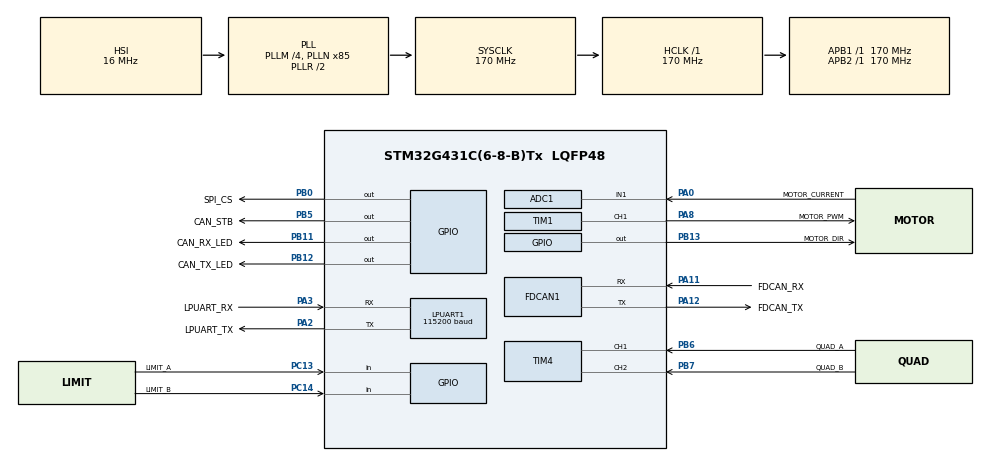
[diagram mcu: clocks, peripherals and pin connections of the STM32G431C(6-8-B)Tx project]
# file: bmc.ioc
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ADC1.Channel-0\#ChannelRegularConversion=ADC_CHANNEL_1
ADC1.NbrOfConversionFlag=1
ADC1.OffsetNumber-0\#ChannelRegularConversion=ADC_OFFSET_NONE
ADC1.Rank-0\#ChannelRegularConversion=1
ADC1.SamplingTime-0\#ChannelRegularConversion=ADC_SAMPLETIME_2CYCLES_5
ADC1.master=1
Dma.LPUART1_TX.0.Direction=DMA_MEMORY_TO_PERIPH
Dma.LPUART1_TX.0.EventEnable=DISABLE
Dma.LPUART1_TX.0.Instance=DMA1_Channel1
Dma.LPUART1_TX.0.MemDataAlignment=DMA_MDATAALIGN_BYTE
Dma.LPUART1_TX.0.MemInc=DMA_MINC_ENABLE
Dma.LPUART1_TX.0.Mode=DMA_NORMAL
Dma.LPUART1_TX.0.PeriphDataAlignment=DMA_PDATAALIGN_BYTE
Dma.LPUART1_TX.0.PeriphInc=DMA_PINC_DISABLE
Dma.LPUART1_TX.0.Polarity=HAL_DMAMUX_REQ_GEN_RISING
Dma.LPUART1_TX.0.Priority=DMA_PRIORITY_LOW
Dma.LPUART1_TX.0.RequestNumber=1
Dma.LPUART1_TX.0.SignalID=NONE
Dma.LPUART1_TX.0.SyncEnable=DISABLE
Dma.LPUART1_TX.0.SyncPolarity=HAL_DMAMUX_SYNC_NO_EVENT
Dma.LPUART1_TX.0.SyncRequestNumber=1
Dma.LPUART1_TX.0.SyncSignalID=NONE
Dma.Request0=LPUART1_TX
FDCAN1.AutoRetransmission=ENABLE
FDCAN1.CalculateBaudRateNominal=999999
FDCAN1.CalculateTimeBitNominal=1000
FDCAN1.CalculateTimeQuantumNominal=11.764705882352942
FDCAN1.ClockDivider=FDCAN_CLOCK_DIV2
FDCAN1.DataSyncJumpWidth=5
FDCAN1.DataTimeSeg1=11
FDCAN1.DataTimeSeg2=5
FDCAN1.ExtFiltersNbr=3
FDCAN1.FrameFormat=FDCAN_FRAME_FD_BRS
FDCAN1.NominalPrescaler=1
FDCAN1.NominalSyncJumpWidth=16
FDCAN1.NominalTimeSeg1=56
FDCAN1.NominalTimeSeg2=28
LPUART1.BaudRate=115200
Mcu.Family=STM32G4
Mcu.Name=STM32G431C(6-8-B)Tx
Mcu.Package=LQFP48
NVIC.DMA1_Channel1_IRQn=true\:7\:0\:true\:false\:true\:false\:true\:true
NVIC.FDCAN1_IT0_IRQn=true\:1\:0\:true\:false\:true\:true\:true\:true
NVIC.FDCAN1_IT1_IRQn=true\:1\:0\:true\:false\:true\:true\:true\:true
NVIC.LPUART1_IRQn=true\:8\:0\:true\:false\:true\:true\:true\:true
NVIC.PriorityGroup=NVIC_PRIORITYGROUP_4
NVIC.TIM1_BRK_TIM15_IRQn=true\:1\:0\:true\:false\:true\:true\:true\:true
NVIC.TIM1_TRG_COM_TIM17_IRQn=true\:1\:0\:true\:false\:true\:true\:true\:true
NVIC.TIM1_UP_TIM16_IRQn=true\:1\:0\:true\:false\:true\:true\:true\:true
NVIC.TIM4_IRQn=true\:1\:0\:true\:false\:true\:true\:true\:true
NVIC.TIM6_DAC_IRQn=true\:0\:0\:false\:false\:true\:true\:true\:true
PA0.GPIO_Label=MOTOR_CURRENT
PA0.Mode=IN1-Single-Ended
PA0.Signal=ADC1_IN1
PA11.GPIO_Label=FDCAN_RX
PA11.GPIO_Speed=GPIO_SPEED_FREQ_VERY_HIGH
PA11.Mode=FDCAN_Activate
PA11.Signal=FDCAN1_RX
PA12.GPIO_Label=FDCAN_TX
PA12.GPIO_Speed=GPIO_SPEED_FREQ_VERY_HIGH
PA12.Mode=FDCAN_Activate
PA12.Signal=FDCAN1_TX
PA13.GPIO_Label=SWDIO
PA13.Mode=Trace_Asynchronous_SW
PA13.Signal=SYS_JTMS-SWDIO
PA14.GPIO_Label=SWCLK
PA14.Mode=Trace_Asynchronous_SW
PA14.Signal=SYS_JTCK-SWCLK
PA2.GPIO_Label=LPUART_TX
PA2.Mode=Asynchronous
PA2.Signal=LPUART1_TX
PA3.GPIO_Label=LPUART_RX
PA3.Mode=Asynchronous
PA3.Signal=LPUART1_RX
PA8.GPIO_Label=MOTOR_PWM
PA8.Signal=S_TIM1_CH1
PB0.GPIO_Label=SPI_CS
PB0.Signal=GPIO_Output
PB11.GPIO_Label=CAN_RX_LED
PB11.Signal=GPIO_Output
PB12.GPIO_Label=CAN_TX_LED
PB12.Signal=GPIO_Output
PB13.GPIO_Label=MOTOR_DIR
PB13.Signal=GPIO_Output
PB3.GPIO_Label=SWO
PB3.Mode=Trace_Asynchronous_SW
PB3.Signal=SYS_JTDO-SWO
PB5.GPIO_Label=CAN_STB
PB5.Signal=GPIO_Output
PB6.GPIO_Label=QUAD_A
PB6.Signal=S_TIM4_CH1
PB7.GPIO_Label=QUAD_B
PB7.Signal=S_TIM4_CH2
PB9.GPIO_FM9=SYSCFG_FASTMODEPLUS_PB9
PB9.GPIO_Label=I2C_SDA
PB9.GPIO_Speed=GPIO_SPEED_FREQ_VERY_HIGH
PB9.Signal=I2C1_SDA
PC13.GPIO_Label=LIMIT_A
PC13.GPIO_PuPd=GPIO_PULLUP
PC13.Signal=GPIO_Input
PC14-OSC32_IN.GPIO_Label=LIMIT_B
PC14-OSC32_IN.GPIO_PuPd=GPIO_PULLUP
PC14-OSC32_IN.Signal=GPIO_Input
ProjectManager.HeapSize=0x200
ProjectManager.StackSize=0x400
ProjectManager.TargetToolchain=CMake
RCC.ADC12Freq_Value=170000000
RCC.AHBFreq_Value=170000000
RCC.APB1Freq_Value=170000000
RCC.APB1TimFreq_Value=170000000
RCC.APB2Freq_Value=170000000
RCC.APB2TimFreq_Value=170000000
RCC.CortexFreq_Value=170000000
RCC.EXTERNAL_CLOCK_VALUE=12288000
RCC.HCLKFreq_Value=170000000
RCC.HSE_VALUE=8000000
RCC.HSI48_VALUE=48000000
RCC.HSI_VALUE=16000000
RCC.LSE_VALUE=32768
RCC.PLLM=RCC_PLLM_DIV4
RCC.PLLN=85
RCC.SYSCLKFreq_VALUE=170000000
RCC.SYSCLKSource=RCC_SYSCLKSOURCE_PLLCLK
RCC.USBFreq_Value=170000000
RCC.VCOOutputFreq_Value=340000000
SH.S_TIM1_CH1.0=TIM1_CH1,PWM Generation1 CH1
SH.S_TIM4_CH1.0=TIM4_CH1,Encoder_Interface
SH.S_TIM4_CH2.0=TIM4_CH2,Encoder_Interface
TIM1.Channel-PWM\ Generation1\ CH1=TIM_CHANNEL_1
TIM1.PeriodNoDither=99
TIM1.Prescaler=63
TIM15.PeriodNoDither=54580
TIM15.Prescaler=511
TIM16.PeriodNoDither=9999
TIM16.Prescaler=1699
TIM17.PeriodNoDither=3999
TIM17.Prescaler=1699
TIM2.Prescaler=169
TIM4.EncoderMode=TIM_ENCODERMODE_TI12
TIM4.IC1Filter=15
TIM4.IC2Filter=15
TIM6.AutoReloadPreload=TIM_AUTORELOAD_PRELOAD_ENABLE
TIM6.PeriodNoDither=9999
TIM6.Prescaler=1699
VP_SYS_VS_DBSignals.Mode=DisableDeadBatterySignals
VP_TIM15_VS_ClockSourceINT.Mode=Internal
VP_TIM16_VS_ClockSourceINT.Mode=Enable_Timer
VP_TIM17_VS_ClockSourceINT.Mode=Enable_Timer
VP_TIM2_VS_ClockSourceINT.Mode=Internal
VP_TIM6_VS_ClockSourceINT.Mode=Enable_Timer
VP_TIM8_VS_ClockSourceINT.Mode=Internal
board=custom

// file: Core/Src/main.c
/* USER CODE BEGIN Header */
/**
  ******************************************************************************
  * @file           : main.c
  * @brief          : Main program body
  ******************************************************************************
  * @attention
  *
  * Copyright (c) 2025 STMicroelectronics.
  * All rights reserved.
  *
  * This software is licensed under terms that can be found in the LICENSE file
  * in the root directory of this software component.
  * If no LICENSE file comes with this software, it is provided AS-IS.
  *
  ******************************************************************************
  */
/* USER CODE END Header */
#include "main.h"

ADC_HandleTypeDef hadc1;

FDCAN_HandleTypeDef hfdcan1;

UART_HandleTypeDef hlpuart1;
DMA_HandleTypeDef hdma_lpuart1_tx;

TIM_HandleTypeDef htim1;
TIM_HandleTypeDef htim2;
TIM_HandleTypeDef htim4;
TIM_HandleTypeDef htim6;
TIM_HandleTypeDef htim8;
TIM_HandleTypeDef htim15;
TIM_HandleTypeDef htim16;
TIM_HandleTypeDef htim17;

void SystemClock_Config(void);
static void MX_GPIO_Init(void);
static void MX_DMA_Init(void);
static void MX_FDCAN1_Init(void);
static void MX_LPUART1_UART_Init(void);
static void MX_TIM1_Init(void);
static void MX_TIM2_Init(void);
static void MX_TIM4_Init(void);
static void MX_TIM6_Init(void);
static void MX_TIM8_Init(void);
static void MX_TIM15_Init(void);
static void MX_TIM16_Init(void);
static void MX_TIM17_Init(void);
static void MX_ADC1_Init(void);

int main(void)
{

  /* MCU Configuration--------------------------------------------------------*/

  /* Reset of all peripherals, Initializes the Flash interface and the Systick. */
  HAL_Init();

  /* Configure the system clock */
  SystemClock_Config();

  /* Initialize all configured peripherals */
  MX_GPIO_Init();
  MX_DMA_Init();
  MX_FDCAN1_Init();
  MX_LPUART1_UART_Init();
  MX_TIM1_Init();
  MX_TIM2_Init();
  MX_TIM4_Init();
  MX_TIM6_Init();
  MX_TIM8_Init();
  MX_TIM15_Init();
  MX_TIM16_Init();
  MX_TIM17_Init();
  MX_ADC1_Init();
  /* USER CODE BEGIN 2 */
  PostInit();
  /* USER CODE END 2 */

  /* Infinite loop */
  /* USER CODE BEGIN WHILE */
  Loop();
    /* USER CODE END WHILE */

}

void SystemClock_Config(void)
{
  RCC_OscInitTypeDef RCC_OscInitStruct = {0};
  RCC_ClkInitTypeDef RCC_ClkInitStruct = {0};

  /** Configure the main internal regulator output voltage
  */
  HAL_PWREx_ControlVoltageScaling(PWR_REGULATOR_VOLTAGE_SCALE1_BOOST);

  /** Initializes the RCC Oscillators according to the specified parameters
  * in the RCC_OscInitTypeDef structure.
  */
  RCC_OscInitStruct.OscillatorType = RCC_OSCILLATORTYPE_HSI;
  RCC_OscInitStruct.HSIState = RCC_HSI_ON;
  RCC_OscInitStruct.HSICalibrationValue = RCC_HSICALIBRATION_DEFAULT;
  RCC_OscInitStruct.PLL.PLLState = RCC_PLL_ON;
  RCC_OscInitStruct.PLL.PLLSource = RCC_PLLSOURCE_HSI;
  RCC_OscInitStruct.PLL.PLLM = RCC_PLLM_DIV4;
  RCC_OscInitStruct.PLL.PLLN = 85;
  RCC_OscInitStruct.PLL.PLLP = RCC_PLLP_DIV2;
  RCC_OscInitStruct.PLL.PLLQ = RCC_PLLQ_DIV2;
  RCC_OscInitStruct.PLL.PLLR = RCC_PLLR_DIV2;
  if (HAL_RCC_OscConfig(&RCC_OscInitStruct) != HAL_OK)
  {
    Error_Handler();
  }

  /** Initializes the CPU, AHB and APB buses clocks
  */
  RCC_ClkInitStruct.ClockType = RCC_CLOCKTYPE_HCLK|RCC_CLOCKTYPE_SYSCLK
                              |RCC_CLOCKTYPE_PCLK1|RCC_CLOCKTYPE_PCLK2;
  RCC_ClkInitStruct.SYSCLKSource = RCC_SYSCLKSOURCE_PLLCLK;
  RCC_ClkInitStruct.AHBCLKDivider = RCC_SYSCLK_DIV1;
  RCC_ClkInitStruct.APB1CLKDivider = RCC_HCLK_DIV1;
  RCC_ClkInitStruct.APB2CLKDivider = RCC_HCLK_DIV1;

  if (HAL_RCC_ClockConfig(&RCC_ClkInitStruct, FLASH_LATENCY_4) != HAL_OK)
  {
    Error_Handler();
  }
}

static void MX_ADC1_Init(void)
{

  ADC_MultiModeTypeDef multimode = {0};
  ADC_ChannelConfTypeDef sConfig = {0};

  /** Common config
  */
  hadc1.Instance = ADC1;
  hadc1.Init.ClockPrescaler = ADC_CLOCK_SYNC_PCLK_DIV4;
  hadc1.Init.Resolution = ADC_RESOLUTION_12B;
  hadc1.Init.DataAlign = ADC_DATAALIGN_RIGHT;
  hadc1.Init.GainCompensation = 0;
  hadc1.Init.ScanConvMode = ADC_SCAN_DISABLE;
  hadc1.Init.EOCSelection = ADC_EOC_SINGLE_CONV;
  hadc1.Init.LowPowerAutoWait = DISABLE;
  hadc1.Init.ContinuousConvMode = DISABLE;
  hadc1.Init.NbrOfConversion = 1;
  hadc1.Init.DiscontinuousConvMode = DISABLE;
  hadc1.Init.ExternalTrigConv = ADC_SOFTWARE_START;
  hadc1.Init.ExternalTrigConvEdge = ADC_EXTERNALTRIGCONVEDGE_NONE;
  hadc1.Init.DMAContinuousRequests = DISABLE;
  hadc1.Init.Overrun = ADC_OVR_DATA_PRESERVED;
  hadc1.Init.OversamplingMode = DISABLE;
  if (HAL_ADC_Init(&hadc1) != HAL_OK)
  {
    Error_Handler();
  }

  /** Configure the ADC multi-mode
  */
  multimode.Mode = ADC_MODE_INDEPENDENT;
  if (HAL_ADCEx_MultiModeConfigChannel(&hadc1, &multimode) != HAL_OK)
  {
    Error_Handler();
  }

  /** Configure Regular Channel
  */
  sConfig.Channel = ADC_CHANNEL_1;
  sConfig.Rank = ADC_REGULAR_RANK_1;
  sConfig.SamplingTime = ADC_SAMPLETIME_2CYCLES_5;
  sConfig.SingleDiff = ADC_SINGLE_ENDED;
  sConfig.OffsetNumber = ADC_OFFSET_NONE;
  sConfig.Offset = 0;
  if (HAL_ADC_ConfigChannel(&hadc1, &sConfig) != HAL_OK)
  {
    Error_Handler();
  }

}

static void MX_FDCAN1_Init(void)
{

  hfdcan1.Instance = FDCAN1;
  hfdcan1.Init.ClockDivider = FDCAN_CLOCK_DIV2;
  hfdcan1.Init.FrameFormat = FDCAN_FRAME_FD_BRS;
  hfdcan1.Init.Mode = FDCAN_MODE_NORMAL;
  hfdcan1.Init.AutoRetransmission = ENABLE;
  hfdcan1.Init.TransmitPause = DISABLE;
  hfdcan1.Init.ProtocolException = DISABLE;
  hfdcan1.Init.NominalPrescaler = 1;
  hfdcan1.Init.NominalSyncJumpWidth = 16;
  hfdcan1.Init.NominalTimeSeg1 = 56;
  hfdcan1.Init.NominalTimeSeg2 = 28;
  hfdcan1.Init.DataPrescaler = 1;
  hfdcan1.Init.DataSyncJumpWidth = 5;
  hfdcan1.Init.DataTimeSeg1 = 11;
  hfdcan1.Init.DataTimeSeg2 = 5;
  hfdcan1.Init.StdFiltersNbr = 0;
  hfdcan1.Init.ExtFiltersNbr = 3;
  hfdcan1.Init.TxFifoQueueMode = FDCAN_TX_FIFO_OPERATION;
  if (HAL_FDCAN_Init(&hfdcan1) != HAL_OK)
  {
    Error_Handler();
  }

}

static void MX_LPUART1_UART_Init(void)
{

  hlpuart1.Instance = LPUART1;
  hlpuart1.Init.BaudRate = 115200;
  hlpuart1.Init.WordLength = UART_WORDLENGTH_8B;
  hlpuart1.Init.StopBits = UART_STOPBITS_1;
  hlpuart1.Init.Parity = UART_PARITY_NONE;
  hlpuart1.Init.Mode = UART_MODE_TX_RX;
  hlpuart1.Init.HwFlowCtl = UART_HWCONTROL_NONE;
  hlpuart1.Init.OneBitSampling = UART_ONE_BIT_SAMPLE_DISABLE;
  hlpuart1.Init.ClockPrescaler = UART_PRESCALER_DIV1;
  hlpuart1.AdvancedInit.AdvFeatureInit = UART_ADVFEATURE_NO_INIT;
  if (HAL_UART_Init(&hlpuart1) != HAL_OK)
  {
    Error_Handler();
  }
  if (HAL_UARTEx_SetTxFifoThreshold(&hlpuart1, UART_TXFIFO_THRESHOLD_1_8) != HAL_OK)
  {
    Error_Handler();
  }
  if (HAL_UARTEx_SetRxFifoThreshold(&hlpuart1, UART_RXFIFO_THRESHOLD_1_8) != HAL_OK)
  {
    Error_Handler();
  }
  if (HAL_UARTEx_DisableFifoMode(&hlpuart1) != HAL_OK)
  {
    Error_Handler();
  }

}

static void MX_TIM1_Init(void)
{

  TIM_MasterConfigTypeDef sMasterConfig = {0};
  TIM_OC_InitTypeDef sConfigOC = {0};
  TIM_BreakDeadTimeConfigTypeDef sBreakDeadTimeConfig = {0};

  htim1.Instance = TIM1;
  htim1.Init.Prescaler = 63;
  htim1.Init.CounterMode = TIM_COUNTERMODE_UP;
  htim1.Init.Period = 99;
  htim1.Init.ClockDivision = TIM_CLOCKDIVISION_DIV1;
  htim1.Init.RepetitionCounter = 0;
  htim1.Init.AutoReloadPreload = TIM_AUTORELOAD_PRELOAD_DISABLE;
  if (HAL_TIM_PWM_Init(&htim1) != HAL_OK)
  {
    Error_Handler();
  }
  sMasterConfig.MasterOutputTrigger = TIM_TRGO_RESET;
  sMasterConfig.MasterOutputTrigger2 = TIM_TRGO2_RESET;
  sMasterConfig.MasterSlaveMode = TIM_MASTERSLAVEMODE_DISABLE;
  if (HAL_TIMEx_MasterConfigSynchronization(&htim1, &sMasterConfig) != HAL_OK)
  {
    Error_Handler();
  }
  sConfigOC.OCMode = TIM_OCMODE_PWM1;
  sConfigOC.Pulse = 0;
  sConfigOC.OCPolarity = TIM_OCPOLARITY_HIGH;
  sConfigOC.OCNPolarity = TIM_OCNPOLARITY_HIGH;
  sConfigOC.OCFastMode = TIM_OCFAST_DISABLE;
  sConfigOC.OCIdleState = TIM_OCIDLESTATE_RESET;
  sConfigOC.OCNIdleState = TIM_OCNIDLESTATE_RESET;
  if (HAL_TIM_PWM_ConfigChannel(&htim1, &sConfigOC, TIM_CHANNEL_1) != HAL_OK)
  {
    Error_Handler();
  }
  sBreakDeadTimeConfig.OffStateRunMode = TIM_OSSR_DISABLE;
  sBreakDeadTimeConfig.OffStateIDLEMode = TIM_OSSI_DISABLE;
  sBreakDeadTimeConfig.LockLevel = TIM_LOCKLEVEL_OFF;
  sBreakDeadTimeConfig.DeadTime = 0;
  sBreakDeadTimeConfig.BreakState = TIM_BREAK_DISABLE;
  sBreakDeadTimeConfig.BreakPolarity = TIM_BREAKPOLARITY_HIGH;
  sBreakDeadTimeConfig.BreakFilter = 0;
  sBreakDeadTimeConfig.BreakAFMode = TIM_BREAK_AFMODE_INPUT;
  sBreakDeadTimeConfig.Break2State = TIM_BREAK2_DISABLE;
  sBreakDeadTimeConfig.Break2Polarity = TIM_BREAK2POLARITY_HIGH;
  sBreakDeadTimeConfig.Break2Filter = 0;
  sBreakDeadTimeConfig.Break2AFMode = TIM_BREAK_AFMODE_INPUT;
  sBreakDeadTimeConfig.AutomaticOutput = TIM_AUTOMATICOUTPUT_DISABLE;
  if (HAL_TIMEx_ConfigBreakDeadTime(&htim1, &sBreakDeadTimeConfig) != HAL_OK)
  {
    Error_Handler();
  }
  HAL_TIM_MspPostInit(&htim1);

}

static void MX_TIM2_Init(void)
{

  TIM_ClockConfigTypeDef sClockSourceConfig = {0};
  TIM_MasterConfigTypeDef sMasterConfig = {0};

  htim2.Instance = TIM2;
  htim2.Init.Prescaler = 169;
  htim2.Init.CounterMode = TIM_COUNTERMODE_UP;
  htim2.Init.Period = 4294967295;
  htim2.Init.ClockDivision = TIM_CLOCKDIVISION_DIV1;
  htim2.Init.AutoReloadPreload = TIM_AUTORELOAD_PRELOAD_DISABLE;
  if (HAL_TIM_Base_Init(&htim2) != HAL_OK)
  {
    Error_Handler();
  }
  sClockSourceConfig.ClockSource = TIM_CLOCKSOURCE_INTERNAL;
  if (HAL_TIM_ConfigClockSource(&htim2, &sClockSourceConfig) != HAL_OK)
  {
    Error_Handler();
  }
  sMasterConfig.MasterOutputTrigger = TIM_TRGO_RESET;
  sMasterConfig.MasterSlaveMode = TIM_MASTERSLAVEMODE_DISABLE;
  if (HAL_TIMEx_MasterConfigSynchronization(&htim2, &sMasterConfig) != HAL_OK)
  {
    Error_Handler();
  }

}

static void MX_TIM4_Init(void)
{

  TIM_Encoder_InitTypeDef sConfig = {0};
  TIM_MasterConfigTypeDef sMasterConfig = {0};

  htim4.Instance = TIM4;
  htim4.Init.Prescaler = 0;
  htim4.Init.CounterMode = TIM_COUNTERMODE_UP;
  htim4.Init.Period = 65535;
  htim4.Init.ClockDivision = TIM_CLOCKDIVISION_DIV1;
  htim4.Init.AutoReloadPreload = TIM_AUTORELOAD_PRELOAD_DISABLE;
  sConfig.EncoderMode = TIM_ENCODERMODE_TI12;
  sConfig.IC1Polarity = TIM_ICPOLARITY_RISING;
  sConfig.IC1Selection = TIM_ICSELECTION_DIRECTTI;
  sConfig.IC1Prescaler = TIM_ICPSC_DIV1;
  sConfig.IC1Filter = 15;
  sConfig.IC2Polarity = TIM_ICPOLARITY_RISING;
  sConfig.IC2Selection = TIM_ICSELECTION_DIRECTTI;
  sConfig.IC2Prescaler = TIM_ICPSC_DIV1;
  sConfig.IC2Filter = 15;
  if (HAL_TIM_Encoder_Init(&htim4, &sConfig) != HAL_OK)
  {
    Error_Handler();
  }
  sMasterConfig.MasterOutputTrigger = TIM_TRGO_RESET;
  sMasterConfig.MasterSlaveMode = TIM_MASTERSLAVEMODE_DISABLE;
  if (HAL_TIMEx_MasterConfigSynchronization(&htim4, &sMasterConfig) != HAL_OK)
  {
    Error_Handler();
  }

}

static void MX_TIM6_Init(void)
{

  TIM_MasterConfigTypeDef sMasterConfig = {0};

  htim6.Instance = TIM6;
  htim6.Init.Prescaler = 1699;
  htim6.Init.CounterMode = TIM_COUNTERMODE_UP;
  htim6.Init.Period = 9999;
  htim6.Init.AutoReloadPreload = TIM_AUTORELOAD_PRELOAD_ENABLE;
  if (HAL_TIM_Base_Init(&htim6) != HAL_OK)
  {
    Error_Handler();
  }
  sMasterConfig.MasterOutputTrigger = TIM_TRGO_RESET;
  sMasterConfig.MasterSlaveMode = TIM_MASTERSLAVEMODE_DISABLE;
  if (HAL_TIMEx_MasterConfigSynchronization(&htim6, &sMasterConfig) != HAL_OK)
  {
    Error_Handler();
  }

}

static void MX_TIM8_Init(void)
{

  TIM_ClockConfigTypeDef sClockSourceConfig = {0};
  TIM_MasterConfigTypeDef sMasterConfig = {0};

  htim8.Instance = TIM8;
  htim8.Init.Prescaler = 0;
  htim8.Init.CounterMode = TIM_COUNTERMODE_UP;
  htim8.Init.Period = 65535;
  htim8.Init.ClockDivision = TIM_CLOCKDIVISION_DIV1;
  htim8.Init.RepetitionCounter = 0;
  htim8.Init.AutoReloadPreload = TIM_AUTORELOAD_PRELOAD_DISABLE;
  if (HAL_TIM_Base_Init(&htim8) != HAL_OK)
  {
    Error_Handler();
  }
  sClockSourceConfig.ClockSource = TIM_CLOCKSOURCE_INTERNAL;
  if (HAL_TIM_ConfigClockSource(&htim8, &sClockSourceConfig) != HAL_OK)
  {
    Error_Handler();
  }
  sMasterConfig.MasterOutputTrigger = TIM_TRGO_RESET;
  sMasterConfig.MasterOutputTrigger2 = TIM_TRGO2_RESET;
  sMasterConfig.MasterSlaveMode = TIM_MASTERSLAVEMODE_DISABLE;
  if (HAL_TIMEx_MasterConfigSynchronization(&htim8, &sMasterConfig) != HAL_OK)
  {
    Error_Handler();
  }

}

static void MX_TIM15_Init(void)
{

  TIM_ClockConfigTypeDef sClockSourceConfig = {0};
  TIM_MasterConfigTypeDef sMasterConfig = {0};

  htim15.Instance = TIM15;
  htim15.Init.Prescaler = 511;
  htim15.Init.CounterMode = TIM_COUNTERMODE_UP;
  htim15.Init.Period = 54580;
  htim15.Init.ClockDivision = TIM_CLOCKDIVISION_DIV1;
  htim15.Init.RepetitionCounter = 0;
  htim15.Init.AutoReloadPreload = TIM_AUTORELOAD_PRELOAD_DISABLE;
  if (HAL_TIM_Base_Init(&htim15) != HAL_OK)
  {
    Error_Handler();
  }
  sClockSourceConfig.ClockSource = TIM_CLOCKSOURCE_INTERNAL;
  if (HAL_TIM_ConfigClockSource(&htim15, &sClockSourceConfig) != HAL_OK)
  {
    Error_Handler();
  }
  sMasterConfig.MasterOutputTrigger = TIM_TRGO_RESET;
  sMasterConfig.MasterSlaveMode = TIM_MASTERSLAVEMODE_DISABLE;
  if (HAL_TIMEx_MasterConfigSynchronization(&htim15, &sMasterConfig) != HAL_OK)
  {
    Error_Handler();
  }

}

static void MX_TIM16_Init(void)
{

  htim16.Instance = TIM16;
  htim16.Init.Prescaler = 1699;
  htim16.Init.CounterMode = TIM_COUNTERMODE_UP;
  htim16.Init.Period = 9999;
  htim16.Init.ClockDivision = TIM_CLOCKDIVISION_DIV1;
  htim16.Init.RepetitionCounter = 0;
  htim16.Init.AutoReloadPreload = TIM_AUTORELOAD_PRELOAD_DISABLE;
  if (HAL_TIM_Base_Init(&htim16) != HAL_OK)
  {
    Error_Handler();
  }

}

static void MX_TIM17_Init(void)
{

  htim17.Instance = TIM17;
  htim17.Init.Prescaler = 1699;
  htim17.Init.CounterMode = TIM_COUNTERMODE_UP;
  htim17.Init.Period = 3999;
  htim17.Init.ClockDivision = TIM_CLOCKDIVISION_DIV1;
  htim17.Init.RepetitionCounter = 0;
  htim17.Init.AutoReloadPreload = TIM_AUTORELOAD_PRELOAD_DISABLE;
  if (HAL_TIM_Base_Init(&htim17) != HAL_OK)
  {
    Error_Handler();
  }

}

static void MX_DMA_Init(void)
{

  /* DMA controller clock enable */
  __HAL_RCC_DMAMUX1_CLK_ENABLE();
  __HAL_RCC_DMA1_CLK_ENABLE();

  /* DMA interrupt init */
  /* DMA1_Channel1_IRQn interrupt configuration */
  HAL_NVIC_SetPriority(DMA1_Channel1_IRQn, 7, 0);
  HAL_NVIC_EnableIRQ(DMA1_Channel1_IRQn);

}

static void MX_GPIO_Init(void)
{
  GPIO_InitTypeDef GPIO_InitStruct = {0};

  /* GPIO Ports Clock Enable */
  __HAL_RCC_GPIOC_CLK_ENABLE();
  __HAL_RCC_GPIOA_CLK_ENABLE();
  __HAL_RCC_GPIOB_CLK_ENABLE();

  /*Configure GPIO pin Output Level */
  HAL_GPIO_WritePin(GPIOB, SPI_CS_Pin|CAN_RX_LED_Pin|CAN_TX_LED_Pin|MOTOR_DIR_Pin
                          |CAN_STB_Pin, GPIO_PIN_RESET);

  /*Configure GPIO pins : LIMIT_A_Pin LIMIT_B_Pin */
  GPIO_InitStruct.Pin = LIMIT_A_Pin|LIMIT_B_Pin;
  GPIO_InitStruct.Mode = GPIO_MODE_INPUT;
  GPIO_InitStruct.Pull = GPIO_PULLUP;
  HAL_GPIO_Init(GPIOC, &GPIO_InitStruct);

  /*Configure GPIO pins : SPI_CS_Pin CAN_RX_LED_Pin CAN_TX_LED_Pin MOTOR_DIR_Pin
                           CAN_STB_Pin */
  GPIO_InitStruct.Pin = SPI_CS_Pin|CAN_RX_LED_Pin|CAN_TX_LED_Pin|MOTOR_DIR_Pin
                          |CAN_STB_Pin;
  GPIO_InitStruct.Mode = GPIO_MODE_OUTPUT_PP;
  GPIO_InitStruct.Pull = GPIO_NOPULL;
  GPIO_InitStruct.Speed = GPIO_SPEED_FREQ_LOW;
  HAL_GPIO_Init(GPIOB, &GPIO_InitStruct);

  /*Configure GPIO pin : I2C_SDA_Pin */
  GPIO_InitStruct.Pin = I2C_SDA_Pin;
  GPIO_InitStruct.Mode = GPIO_MODE_AF_OD;
  GPIO_InitStruct.Pull = GPIO_NOPULL;
  GPIO_InitStruct.Speed = GPIO_SPEED_FREQ_VERY_HIGH;
  GPIO_InitStruct.Alternate = GPIO_AF4_I2C1;
  HAL_GPIO_Init(I2C_SDA_GPIO_Port, &GPIO_InitStruct);

  /**/
  __HAL_SYSCFG_FASTMODEPLUS_ENABLE(SYSCFG_FASTMODEPLUS_PB9);

}

void Error_Handler(void)
{
  __disable_irq();
  while (1)
  {
  }
}
